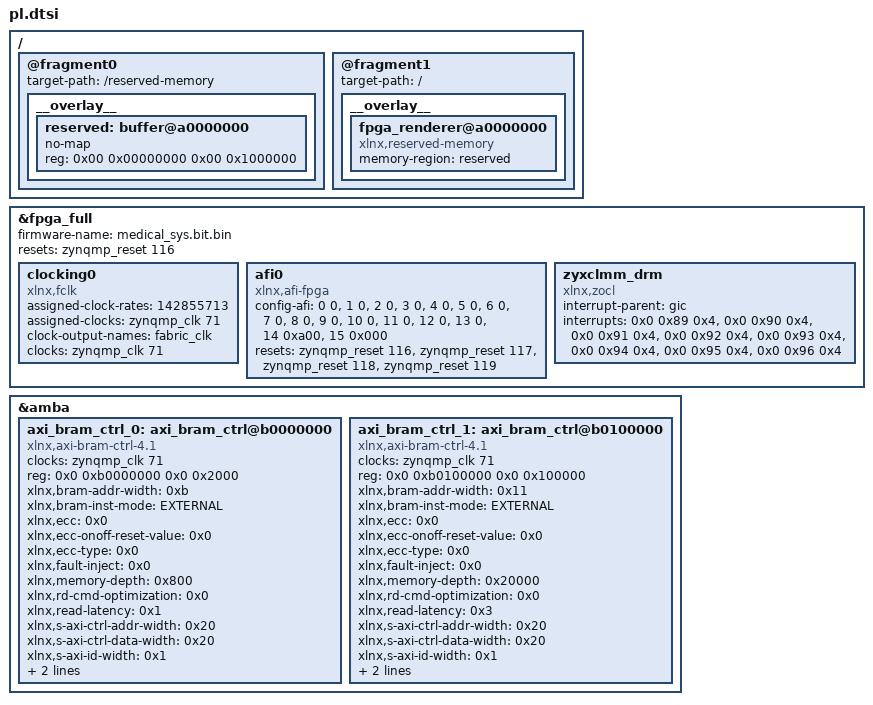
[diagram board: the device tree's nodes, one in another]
/*
 * CAUTION: This file is automatically generated by Xilinx.
 * Version: XSCT 2024.1
 * Today is: Thu Nov  7 23:48:31 2024
 */


/dts-v1/;
/plugin/;
&fpga_full {
	firmware-name = "medical_sys.bit.bin";
	resets = <&zynqmp_reset 116>;
	clocking0: clocking0 {
		#clock-cells = <0>;
		assigned-clock-rates = <142855713>;
		assigned-clocks = <&zynqmp_clk 71>;
		clock-output-names = "fabric_clk";
		clocks = <&zynqmp_clk 71>;
		compatible = "xlnx,fclk";
	};
	afi0: afi0 {
		compatible = "xlnx,afi-fpga";
		config-afi = < 0 0>, <1 0>, <2 0>, <3 0>, <4 0>, <5 0>, <6 0>, <7 0>, <8 0>, <9 0>, <10 0>, <11 0>, <12 0>, <13 0>, <14 0xa00>, <15 0x000>;
		resets = <&zynqmp_reset 116>, <&zynqmp_reset 117>, <&zynqmp_reset 118>, <&zynqmp_reset 119>;
	};
	zyxclmm_drm {
		compatible = "xlnx,zocl";
		interrupt-parent = <&gic>;
		interrupts = <0x0 0x89 0x4>, <0x0 0x90 0x4>, <0x0 0x91 0x4>, <0x0 0x92 0x4>, <0x0 0x93 0x4>, <0x0 0x94 0x4>, <0x0 0x95 0x4>, <0x0 0x96 0x4>;
	};
};
&amba {
	#address-cells = <2>;
	#size-cells = <2>;
	axi_bram_ctrl_0: axi_bram_ctrl@b0000000 {
		/* This is a place holder node for a custom IP, user may need to update the entries */
		clock-names = "s_axi_aclk";
		clocks = <&zynqmp_clk 71>;
		compatible = "xlnx,axi-bram-ctrl-4.1";
		reg = <0x0 0xb0000000 0x0 0x2000>;
		xlnx,bram-addr-width = <0xb>;
		xlnx,bram-inst-mode = "EXTERNAL";
		xlnx,ecc = <0x0>;
		xlnx,ecc-onoff-reset-value = <0x0>;
		xlnx,ecc-type = <0x0>;
		xlnx,fault-inject = <0x0>;
		xlnx,memory-depth = <0x800>;
		xlnx,rd-cmd-optimization = <0x0>;
		xlnx,read-latency = <0x1>;
		xlnx,s-axi-ctrl-addr-width = <0x20>;
		xlnx,s-axi-ctrl-data-width = <0x20>;
		xlnx,s-axi-id-width = <0x1>;
		xlnx,s-axi-supports-narrow-burst = <0x0>;
		xlnx,single-port-bram = <0x1>;
	};
	axi_bram_ctrl_1: axi_bram_ctrl@b0100000 {
		/* This is a place holder node for a custom IP, user may need to update the entries */
		clock-names = "s_axi_aclk";
		clocks = <&zynqmp_clk 71>;
		compatible = "xlnx,axi-bram-ctrl-4.1";
		reg = <0x0 0xb0100000 0x0 0x100000>;
		xlnx,bram-addr-width = <0x11>;
		xlnx,bram-inst-mode = "EXTERNAL";
		xlnx,ecc = <0x0>;
		xlnx,ecc-onoff-reset-value = <0x0>;
		xlnx,ecc-type = <0x0>;
		xlnx,fault-inject = <0x0>;
		xlnx,memory-depth = <0x20000>;
		xlnx,rd-cmd-optimization = <0x0>;
		xlnx,read-latency = <0x3>;
		xlnx,s-axi-ctrl-addr-width = <0x20>;
		xlnx,s-axi-ctrl-data-width = <0x20>;
		xlnx,s-axi-id-width = <0x1>;
		xlnx,s-axi-supports-narrow-burst = <0x0>;
		xlnx,single-port-bram = <0x1>;
	};
};

/ {
		@fragment0 {
		target-path = "/reserved-memory";
		__overlay__ {
			#address-cells = <0x02>;
			#size-cells = <0x02>;
			ranges;

			reserved: buffer@a0000000 {
				no-map;
				reg = <0x00 0x00000000 0x00 0x1000000>;
			};
		};
	};

	@fragment1 {
		target-path = "/";
		__overlay__ {
			fpga_renderer@a0000000 {
				compatible = "xlnx,reserved-memory";
				memory-region = <&reserved>;
			};
		};
	};
};
